# STM32G431 register map
File version: 2.8
CPU: CM4 r0p1, little endian, MPU, FPU, 4 interrupt priority bits
Registers are 32-bit, read-write, reset 0x0 unless marked. A register's access mark holds for its fields unless they carry their own. Offsets are from the block's base; [hi:lo] are bit positions; {n}, {i} and the like mark numbered series.

## RNG — Random number generator
Base 0x50060800
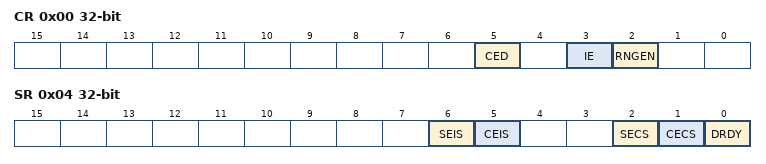
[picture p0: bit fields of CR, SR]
0x00 CR — control register
  [5] CED — Clock error detection
    0=Enabled (Clock error detection is enabled); 1=Disabled (Clock error detection is disabled)
  [3] IE — Interrupt enable
    0=Disabled (RNG interrupt is disabled); 1=Enabled (RNG interrupt is enabled)
  [2] RNGEN — Random number generator enable
    0=Disabled (Random number generator is disabled); 1=Enabled (Random number generator is enabled)
0x04 SR access per field — status register
  [6] SEIS rw write-0-clears — Seed error interrupt status
    on write: 0=Clear flag | on read: 0=No faulty sequence detected; 1=Fault (At least one faulty sequence has been detected. See **SECS** bit description for details. An interrupt is pending if IE = 1 in the RNG_CR register.)
  [5] CEIS rw write-0-clears — Clock error interrupt status
    on write: 0=Clear flag | on read: 0=Correct (The RNG clock is correct); 1=Slow (The RNG has been detected too slow An interrupt is pending if IE = 1 in the RNG_CR register)
  [2] SECS ro — Seed error current status
    0=No faulty sequence has currently been detected. If the SEIS bit is set, this means that a faulty sequence was detected and the situation has been recovered.; 1=Fault (At least one faulty sequence has been detected - see ref manual for details)
  [1] CECS ro — Clock error current status
    0=Correct (The RNG clock is correct. If the CEIS bit is set, this means that a slow clock was detected and the situation has been recovered.); 1=Slow (The RNG clock is too slow)
  [0] DRDY ro — Data ready
    0=Invalid (The RNG_DR register is not yet valid, no random data is available); 1=Valid (The RNG_DR register contains valid random data. Once the RNG_DR register has been read, this bit returns to 0 until a new random value is generated.)
0x08 DR ro — data register
  [31:0] RNDATA — Random data

## SYSCFG — System configuration controller
Base 0x40010000
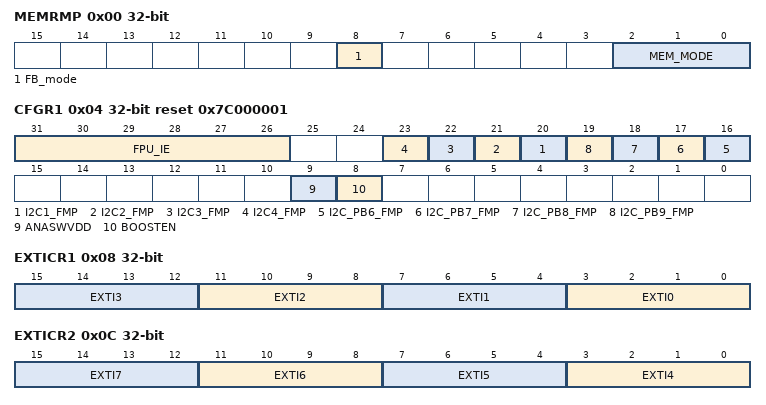
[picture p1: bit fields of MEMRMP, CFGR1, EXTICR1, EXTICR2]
0x00 MEMRMP — Remap Memory register
  [8] FB_mode — User Flash Bank mode
  [2:0] MEM_MODE — Memory mapping selection
0x04 CFGR1 reset 0x7C000001 — peripheral mode configuration register
  [31:26] FPU_IE — FPU Interrupts Enable
  [n+19] I2C{n}_FMP (n=1..4) — I2C1 FM+ drive capability enable
  [n+10] I2C_PB{n}_FMP (n=6..9) — FM+ drive capability on PB6
  [9] ANASWVDD — GPIO analog switch control voltage selection
  [8] BOOSTEN
0x08 EXTICR1 — external interrupt configuration register 1
  [4n+3:4n] EXTI{n} (n=0..3) — EXTI x configuration (x = 0 to 3)
0x0C EXTICR2 — external interrupt configuration register 2
  [4n-13:4n-16] EXTI{n} (n=4..7) — EXTI x configuration (x = 4 to 7)
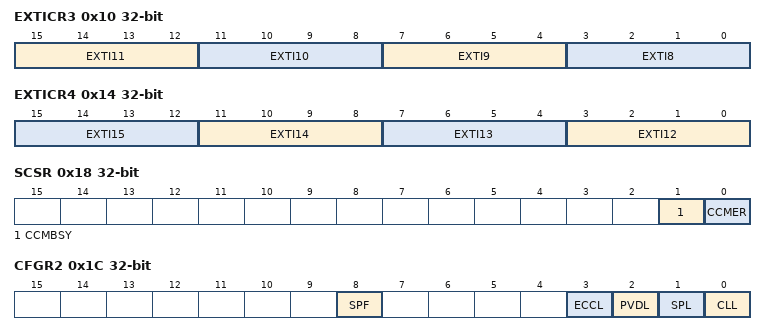
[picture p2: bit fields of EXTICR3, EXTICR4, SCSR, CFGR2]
0x10 EXTICR3 — external interrupt configuration register 3
  [15:12] EXTI11 — EXTI x configuration (x = 8 to 11)
  [11:8] EXTI10
  [7:4] EXTI9 — EXTI x configuration (x = 8 to 11)
  [3:0] EXTI8 — EXTI x configuration (x = 8 to 11)
0x14 EXTICR4 — external interrupt configuration register 4
  [4n-45:4n-48] EXTI{n} (n=12..15) — EXTI x configuration (x = 12 to 15)
0x18 SCSR access per field — CCM SRAM control and status register
  [1] CCMBSY ro — CCM SRAM busy by erase operation
  [0] CCMER rw — CCM SRAM Erase
0x1C CFGR2 — configuration register 2
  [8] SPF — SRAM Parity Flag
  [3] ECCL — ECC Lock
  [2] PVDL — PVD Lock
  [1] SPL — SRAM Parity Lock
  [0] CLL — Core Lockup Lock
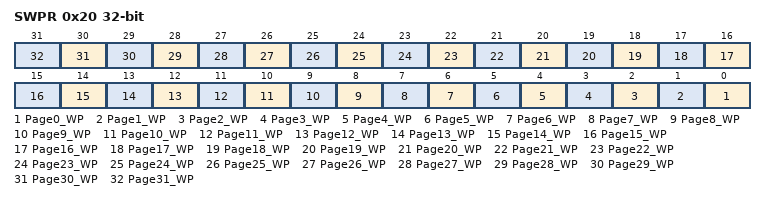
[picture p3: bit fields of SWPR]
0x20 SWPR — SRAM Write protection register 1
  [n] Page{n}_WP (n=0..31) — Write protection
0x24 SKR wo — SRAM2 Key Register
  [7:0] KEY — SRAM2 Key for software erase

## TAMP — Tamper and backup registers
Base 0x40002400
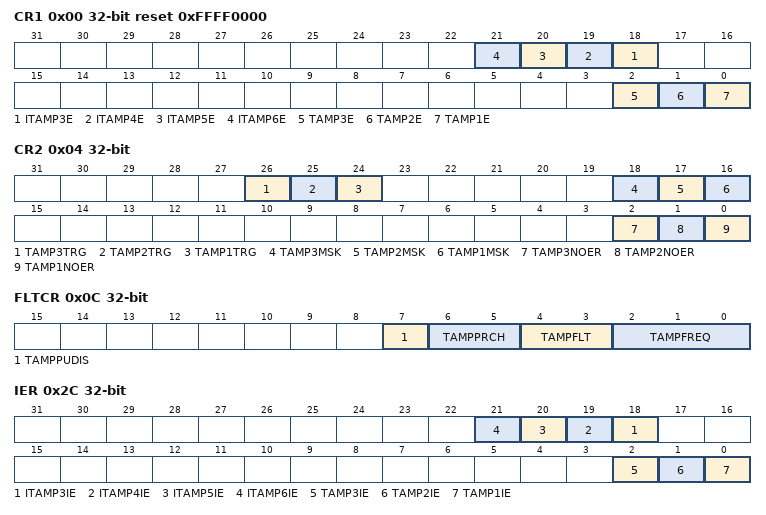
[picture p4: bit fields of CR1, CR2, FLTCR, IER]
0x00 CR1 reset 0xFFFF0000 — control register 1
  [n+15] ITAMP{n}E (n=3..6)
  [2] TAMP3E — TAMP2E
  [1] TAMP2E
  [0] TAMP1E
0x04 CR2 — control register 2
  [26] TAMP3TRG, [25] TAMP2TRG, [24] TAMP1TRG, [18] TAMP3MSK, [17] TAMP2MSK, [16] TAMP1MSK, [2] TAMP3NOER, [1] TAMP2NOER, [0] TAMP1NOER
0x0C FLTCR — TAMP filter control register
  [7] TAMPPUDIS, [6:5] TAMPPRCH, [4:3] TAMPFLT, [2:0] TAMPFREQ
0x2C IER — TAMP interrupt enable register
  [n+15] ITAMP{n}IE (n=3..6), [2] TAMP3IE, [1] TAMP2IE, [0] TAMP1IE
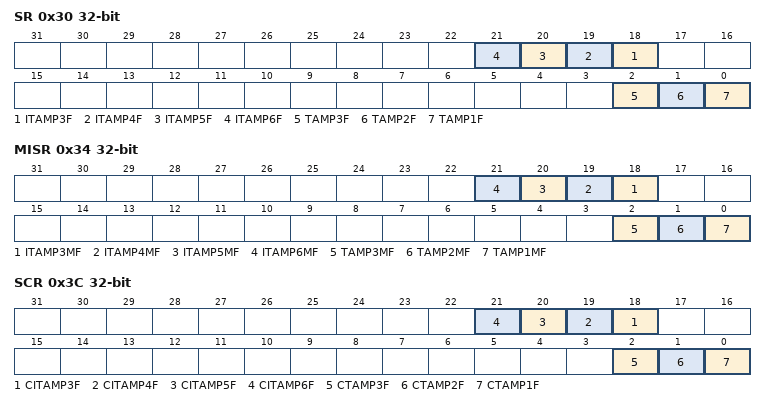
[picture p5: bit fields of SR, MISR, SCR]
0x30 SR ro — TAMP status register
  [n+15] ITAMP{n}F (n=3..6), [2] TAMP3F, [1] TAMP2F, [0] TAMP1F
0x34 MISR ro — TAMP masked interrupt status register
  [n+15] ITAMP{n}MF (n=3..6), [2] TAMP3MF, [1] TAMP2MF, [0] TAMP1MF
0x3C SCR — TAMP status clear register
  [n+15] CITAMP{n}F (n=3..6), [2] CTAMP3F, [1] CTAMP2F, [0] CTAMP1F
{0x100+4i} BKP{i}R (i=0..31) — TAMP backup register
  [31:0] BKP
